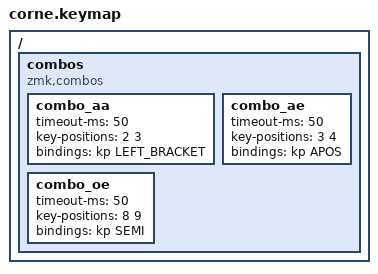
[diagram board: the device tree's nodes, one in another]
// Copyright 2021 Manna Harbour
// https://github.com/manna-harbour/miryoku

#include "../miryoku/custom_config.h"
#include "../miryoku/mapping/42/corne.h"
#include "../miryoku/miryoku.dtsi"

/ {
    combos {
        compatible = "zmk,combos";
        combo_aa {
            timeout-ms = <50>;
            key-positions = <2 3>;
            bindings = <&kp LEFT_BRACKET>;
        };
    };
};

/ {
    combos {
        compatible = "zmk,combos";
        combo_ae {
            timeout-ms = <50>;
            key-positions = <3 4>;
            bindings = <&kp APOS>;
        };
    };
};

/ {
    combos {
        compatible = "zmk,combos";
        combo_oe {
            timeout-ms = <50>;
            key-positions = <8 9>;
            bindings = <&kp SEMI>;
        };
    };
};
